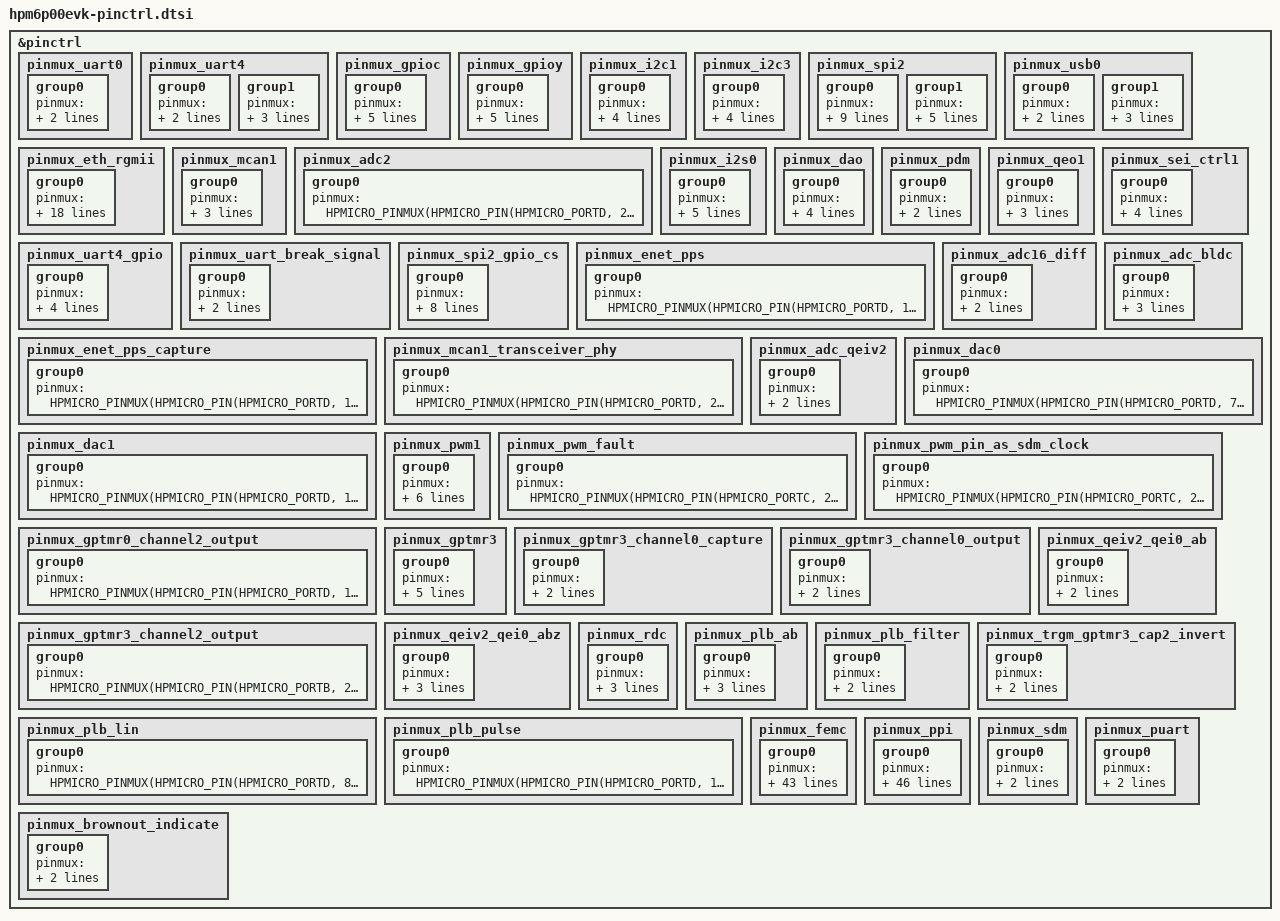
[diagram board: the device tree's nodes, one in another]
/*
* Copyright (c) 2026 HPMicro
* SPDX-License-Identifier: Apache-2.0
*/

#include "dt-bindings/pinctrl/hpmicro-pinctrl-common.h"

&pinctrl {
	pinmux_uart0: pinmux_uart0 {
		group0 {
			pinmux = <HPMICRO_PINMUX(HPMICRO_PIN(HPMICRO_PORTA, 0), IOC_TYPE_IOC, 0, 2)>,
				<HPMICRO_PINMUX(HPMICRO_PIN(HPMICRO_PORTA, 1), IOC_TYPE_IOC, 0, 2)>;
		};
	};

	pinmux_uart4: pinmux_uart4 {
		group0 {
			pinmux = <HPMICRO_PINMUX(HPMICRO_PIN(HPMICRO_PORTY, 0), IOC_TYPE_IOC, 0, 2)>,
				<HPMICRO_PINMUX(HPMICRO_PIN(HPMICRO_PORTY, 0), IOC_TYPE_PIOC, 0, 3)>;
		};

		group1 {
			pinmux = <HPMICRO_PINMUX(HPMICRO_PIN(HPMICRO_PORTY, 1), IOC_TYPE_IOC, 0, 2)>,
				<HPMICRO_PINMUX(HPMICRO_PIN(HPMICRO_PORTY, 1), IOC_TYPE_PIOC, 0, 3)>;
			bias-pull-up;
		};
	};

	pinmux_gpioc: pinmux_gpioc {
		group0 {
			pinmux = <HPMICRO_PINMUX(HPMICRO_PIN(HPMICRO_PORTC, 23), IOC_TYPE_IOC, 0, 0)>;
			drive-open-drain;
			input-enable;
			keeper-capability-disable;
			input-schmitt-enable;
		};
	};

	pinmux_gpioy: pinmux_gpioy {
		group0 {
			pinmux = <HPMICRO_PINMUX(HPMICRO_PIN(HPMICRO_PORTY, 5), IOC_TYPE_IOC, 0, 0)>,
				<HPMICRO_PINMUX(HPMICRO_PIN(HPMICRO_PORTY, 5), IOC_TYPE_PIOC, 0, 3)>;
			bias-pull-up;
			slew-rate = "fast";
			slew-pd = "100M";
		};
	};

	pinmux_i2c1: pinmux_i2c1 {
		group0 {
			pinmux = <HPMICRO_PINMUX(HPMICRO_PIN(HPMICRO_PORTC, 29), IOC_TYPE_IOC, 0, 4)>,
				<HPMICRO_PINMUX(HPMICRO_PIN(HPMICRO_PORTC, 28), IOC_TYPE_IOC, 0, 4)>;
			drive-open-drain;
			input-enable;
		};
	};

	pinmux_i2c3: pinmux_i2c3 {
		group0 {
			pinmux = <HPMICRO_PINMUX(HPMICRO_PIN(HPMICRO_PORTB, 7), IOC_TYPE_IOC, 0, 4)>,
				<HPMICRO_PINMUX(HPMICRO_PIN(HPMICRO_PORTB, 6), IOC_TYPE_IOC, 0, 4)>;
			drive-open-drain;
			input-enable;
		};
	};

	pinmux_spi2: pinmux_spi2 {
		group0 {
			pinmux = <HPMICRO_PINMUX(HPMICRO_PIN(HPMICRO_PORTY, 4), IOC_TYPE_IOC, 0, 5)>,
				<HPMICRO_PINMUX(HPMICRO_PIN(HPMICRO_PORTY, 4), IOC_TYPE_PIOC, 0, 3)>,
				<HPMICRO_PINMUX(HPMICRO_PIN(HPMICRO_PORTY, 6), IOC_TYPE_IOC, 0, 5)>,
				<HPMICRO_PINMUX(HPMICRO_PIN(HPMICRO_PORTY, 6), IOC_TYPE_PIOC, 0, 3)>,
				<HPMICRO_PINMUX(HPMICRO_PIN(HPMICRO_PORTY, 7), IOC_TYPE_IOC, 0, 5)>,
				<HPMICRO_PINMUX(HPMICRO_PIN(HPMICRO_PORTY, 7), IOC_TYPE_PIOC, 0, 3)>;
			input-enable;
			slew-rate = "fast";
			slew-pd = "100M";
		};

		group1 {
			pinmux = <HPMICRO_PINMUX(HPMICRO_PIN(HPMICRO_PORTY, 5), IOC_TYPE_IOC, 0, 0)>,
				<HPMICRO_PINMUX(HPMICRO_PIN(HPMICRO_PORTY, 5), IOC_TYPE_PIOC, 0, 3)>;
			bias-pull-up;
			slew-rate = "fast";
			slew-pd = "100M";
		};
	};

	pinmux_usb0: pinmux_usb0 {
		group0 {
			pinmux = <HPMICRO_PINMUX(HPMICRO_PIN(HPMICRO_PORTD, 0), IOC_TYPE_IOC, 1, 0)>,
				<HPMICRO_PINMUX(HPMICRO_PIN(HPMICRO_PORTD, 1), IOC_TYPE_IOC, 1, 0)>;
		};

		group1 {
			pinmux = <HPMICRO_PINMUX(HPMICRO_PIN(HPMICRO_PORTC, 25), IOC_TYPE_IOC, 0, 24)>,
				<HPMICRO_PINMUX(HPMICRO_PIN(HPMICRO_PORTC, 26), IOC_TYPE_IOC, 0, 24)>,
				<HPMICRO_PINMUX(HPMICRO_PIN(HPMICRO_PORTC, 27), IOC_TYPE_IOC, 0, 24)>;
		};
	};

	pinmux_eth_rgmii: pinmux_eth_rgmii {
		group0 {
			pinmux = <HPMICRO_PINMUX(HPMICRO_PIN(HPMICRO_PORTD, 0), IOC_TYPE_IOC, 0, 18)>,
				<HPMICRO_PINMUX(HPMICRO_PIN(HPMICRO_PORTD, 1), IOC_TYPE_IOC, 0, 18)>,
				<HPMICRO_PINMUX(HPMICRO_PIN(HPMICRO_PORTD, 3), IOC_TYPE_IOC, 0, 18)>,
				<HPMICRO_PINMUX(HPMICRO_PIN(HPMICRO_PORTD, 4), IOC_TYPE_IOC, 0, 18)>,
				<HPMICRO_PINMUX(HPMICRO_PIN(HPMICRO_PORTD, 5), IOC_TYPE_IOC, 0, 18)>,
				<HPMICRO_PINMUX(HPMICRO_PIN(HPMICRO_PORTD, 6), IOC_TYPE_IOC, 0, 18)>,
				<HPMICRO_PINMUX(HPMICRO_PIN(HPMICRO_PORTA, 18), IOC_TYPE_IOC, 0, 18)>,
				<HPMICRO_PINMUX(HPMICRO_PIN(HPMICRO_PORTA, 19), IOC_TYPE_IOC, 0, 18)>,
				<HPMICRO_PINMUX(HPMICRO_PIN(HPMICRO_PORTD, 16), IOC_TYPE_IOC, 0, 18)>,
				<HPMICRO_PINMUX(HPMICRO_PIN(HPMICRO_PORTD, 17), IOC_TYPE_IOC, 0, 18)>,
				<HPMICRO_PINMUX(HPMICRO_PIN(HPMICRO_PORTD, 18), IOC_TYPE_IOC, 0, 18)>,
				<HPMICRO_PINMUX(HPMICRO_PIN(HPMICRO_PORTD, 19), IOC_TYPE_IOC, 0, 18)>,
				<HPMICRO_PINMUX(HPMICRO_PIN(HPMICRO_PORTD, 20), IOC_TYPE_IOC, 0, 18)>,
				<HPMICRO_PINMUX(HPMICRO_PIN(HPMICRO_PORTD, 21), IOC_TYPE_IOC, 0, 18)>;
			input-schmitt-enable;
			slew-rate = "fast";
			slew-pd = "100M";
			drive-strength = "r011";
		};
	};

	pinmux_mcan1: pinmux_mcan1 {
		group0 {
			pinmux = <HPMICRO_PINMUX(HPMICRO_PIN(HPMICRO_PORTD, 30), IOC_TYPE_IOC, 0, 7)>,
				<HPMICRO_PINMUX(HPMICRO_PIN(HPMICRO_PORTD, 31), IOC_TYPE_IOC, 0, 7)>,
				<HPMICRO_PINMUX(HPMICRO_PIN(HPMICRO_PORTD, 29), IOC_TYPE_IOC, 0, 7)>;
		};
	};

	pinmux_adc2: pinmux_adc2 {
		group0 {
			pinmux = <HPMICRO_PINMUX(HPMICRO_PIN(HPMICRO_PORTD, 26), IOC_TYPE_IOC, 1, 0)>;
		};
	};

	pinmux_i2s0: pinmux_i2s0 {
		group0 {
			pinmux = <HPMICRO_PINMUX(HPMICRO_PIN(HPMICRO_PORTA, 20), IOC_TYPE_IOC, 0, 8)>,
				<HPMICRO_PINMUX(HPMICRO_PIN(HPMICRO_PORTA, 21), IOC_TYPE_IOC, 0, 8)>,
				<HPMICRO_PINMUX(HPMICRO_PIN(HPMICRO_PORTA, 22), IOC_TYPE_IOC, 0, 8)>,
				<HPMICRO_PINMUX(HPMICRO_PIN(HPMICRO_PORTB, 0), IOC_TYPE_IOC, 0, 8)>,
				<HPMICRO_PINMUX(HPMICRO_PIN(HPMICRO_PORTA, 23), IOC_TYPE_IOC, 0, 8)>;
		};
	};

	pinmux_dao: pinmux_dao {
		group0 {
			pinmux = <HPMICRO_PINMUX(HPMICRO_PIN(HPMICRO_PORTY, 3), IOC_TYPE_IOC, 0, 9)>,
				<HPMICRO_PINMUX(HPMICRO_PIN(HPMICRO_PORTY, 3), IOC_TYPE_PIOC, 0, 3)>,
				<HPMICRO_PINMUX(HPMICRO_PIN(HPMICRO_PORTY, 2), IOC_TYPE_IOC, 0, 9)>,
				<HPMICRO_PINMUX(HPMICRO_PIN(HPMICRO_PORTY, 2), IOC_TYPE_PIOC, 0, 3)>;
		};
	};

	pinmux_pdm: pinmux_pdm {
		group0 {
			pinmux = <HPMICRO_PINMUX(HPMICRO_PIN(HPMICRO_PORTD, 22), IOC_TYPE_IOC, 0, 9)>,
				<HPMICRO_PINMUX(HPMICRO_PIN(HPMICRO_PORTD, 23), IOC_TYPE_IOC, 0, 9)>;
		};
	};

	pinmux_qeo1: pinmux_qeo1 {
		group0 {
			pinmux = <HPMICRO_PINMUX(HPMICRO_PIN(HPMICRO_PORTC, 0), IOC_TYPE_IOC, 0, 21)>,
				<HPMICRO_PINMUX(HPMICRO_PIN(HPMICRO_PORTC, 1), IOC_TYPE_IOC, 0, 21)>,
				<HPMICRO_PINMUX(HPMICRO_PIN(HPMICRO_PORTC, 2), IOC_TYPE_IOC, 0, 21)>;
		};
	};

	pinmux_sei_ctrl1: pinmux_sei_ctrl1 {
		group0 {
			pinmux = <HPMICRO_PINMUX(HPMICRO_PIN(HPMICRO_PORTB, 8), IOC_TYPE_IOC, 0, 22)>,
				<HPMICRO_PINMUX(HPMICRO_PIN(HPMICRO_PORTB, 9), IOC_TYPE_IOC, 0, 22)>,
				<HPMICRO_PINMUX(HPMICRO_PIN(HPMICRO_PORTB, 10), IOC_TYPE_IOC, 0, 22)>,
				<HPMICRO_PINMUX(HPMICRO_PIN(HPMICRO_PORTB, 11), IOC_TYPE_IOC, 0, 22)>;
		};
	};

	pinmux_uart4_gpio: pinmux_uart4_gpio {
		group0 {
			pinmux = <HPMICRO_PINMUX(HPMICRO_PIN(HPMICRO_PORTY, 0), IOC_TYPE_IOC, 0, 0)>,
				<HPMICRO_PINMUX(HPMICRO_PIN(HPMICRO_PORTY, 0), IOC_TYPE_PIOC, 0, 3)>,
				<HPMICRO_PINMUX(HPMICRO_PIN(HPMICRO_PORTY, 1), IOC_TYPE_IOC, 0, 0)>,
				<HPMICRO_PINMUX(HPMICRO_PIN(HPMICRO_PORTY, 1), IOC_TYPE_PIOC, 0, 3)>;
		};
	};

	pinmux_uart_break_signal: pinmux_uart_break_signal {
		group0 {
			pinmux = <HPMICRO_PINMUX(HPMICRO_PIN(HPMICRO_PORTY, 5), IOC_TYPE_IOC, 0, 0)>,
				<HPMICRO_PINMUX(HPMICRO_PIN(HPMICRO_PORTY, 5), IOC_TYPE_PIOC, 0, 3)>;
		};
	};

	pinmux_spi2_gpio_cs: pinmux_spi2_gpio_cs {
		group0 {
			pinmux = <HPMICRO_PINMUX(HPMICRO_PIN(HPMICRO_PORTY, 5), IOC_TYPE_IOC, 0, 0)>,
				<HPMICRO_PINMUX(HPMICRO_PIN(HPMICRO_PORTY, 5), IOC_TYPE_PIOC, 0, 3)>,
				<HPMICRO_PINMUX(HPMICRO_PIN(HPMICRO_PORTY, 4), IOC_TYPE_IOC, 0, 5)>,
				<HPMICRO_PINMUX(HPMICRO_PIN(HPMICRO_PORTY, 4), IOC_TYPE_PIOC, 0, 3)>,
				<HPMICRO_PINMUX(HPMICRO_PIN(HPMICRO_PORTY, 6), IOC_TYPE_IOC, 0, 5)>,
				<HPMICRO_PINMUX(HPMICRO_PIN(HPMICRO_PORTY, 6), IOC_TYPE_PIOC, 0, 3)>,
				<HPMICRO_PINMUX(HPMICRO_PIN(HPMICRO_PORTY, 7), IOC_TYPE_IOC, 0, 5)>,
				<HPMICRO_PINMUX(HPMICRO_PIN(HPMICRO_PORTY, 7), IOC_TYPE_PIOC, 0, 3)>;
		};
	};

	pinmux_enet_pps: pinmux_enet_pps {
		group0 {
			pinmux = <HPMICRO_PINMUX(HPMICRO_PIN(HPMICRO_PORTD, 11), IOC_TYPE_IOC, 0, 25)>;
		};
	};

	pinmux_enet_pps_capture: pinmux_enet_pps_capture {
		group0 {
			pinmux = <HPMICRO_PINMUX(HPMICRO_PIN(HPMICRO_PORTD, 12), IOC_TYPE_IOC, 0, 25)>;
		};
	};

	pinmux_mcan1_transceiver_phy: pinmux_mcan1_transceiver_phy {
		group0 {
			pinmux = <HPMICRO_PINMUX(HPMICRO_PIN(HPMICRO_PORTD, 29), IOC_TYPE_IOC, 0, 0)>;
		};
	};

	pinmux_adc16_diff: pinmux_adc16_diff {
		group0 {
			pinmux = <HPMICRO_PINMUX(HPMICRO_PIN(HPMICRO_PORTD, 24), IOC_TYPE_IOC, 1, 0)>,
				<HPMICRO_PINMUX(HPMICRO_PIN(HPMICRO_PORTD, 25), IOC_TYPE_IOC, 1, 0)>;
		};
	};

	pinmux_adc_bldc: pinmux_adc_bldc {
		group0 {
			pinmux = <HPMICRO_PINMUX(HPMICRO_PIN(HPMICRO_PORTD, 14), IOC_TYPE_IOC, 1, 0)>,
				<HPMICRO_PINMUX(HPMICRO_PIN(HPMICRO_PORTD, 24), IOC_TYPE_IOC, 1, 0)>,
				<HPMICRO_PINMUX(HPMICRO_PIN(HPMICRO_PORTD, 25), IOC_TYPE_IOC, 1, 0)>;
		};
	};

	pinmux_adc_qeiv2: pinmux_adc_qeiv2 {
		group0 {
			pinmux = <HPMICRO_PINMUX(HPMICRO_PIN(HPMICRO_PORTD, 25), IOC_TYPE_IOC, 1, 0)>,
				<HPMICRO_PINMUX(HPMICRO_PIN(HPMICRO_PORTD, 14), IOC_TYPE_IOC, 1, 0)>;
		};
	};

	pinmux_dac0: pinmux_dac0 {
		group0 {
			pinmux = <HPMICRO_PINMUX(HPMICRO_PIN(HPMICRO_PORTD, 7), IOC_TYPE_IOC, 1, 0)>;
		};
	};

	pinmux_dac1: pinmux_dac1 {
		group0 {
			pinmux = <HPMICRO_PINMUX(HPMICRO_PIN(HPMICRO_PORTD, 17), IOC_TYPE_IOC, 1, 0)>;
		};
	};

	pinmux_pwm1: pinmux_pwm1 {
		group0 {
			pinmux = <HPMICRO_PINMUX(HPMICRO_PIN(HPMICRO_PORTD, 8), IOC_TYPE_IOC, 0, 16)>,
				<HPMICRO_PINMUX(HPMICRO_PIN(HPMICRO_PORTD, 9), IOC_TYPE_IOC, 0, 16)>,
				<HPMICRO_PINMUX(HPMICRO_PIN(HPMICRO_PORTD, 10), IOC_TYPE_IOC, 0, 16)>,
				<HPMICRO_PINMUX(HPMICRO_PIN(HPMICRO_PORTD, 11), IOC_TYPE_IOC, 0, 16)>,
				<HPMICRO_PINMUX(HPMICRO_PIN(HPMICRO_PORTD, 12), IOC_TYPE_IOC, 0, 16)>,
				<HPMICRO_PINMUX(HPMICRO_PIN(HPMICRO_PORTD, 13), IOC_TYPE_IOC, 0, 16)>;
		};
	};

	pinmux_pwm_fault: pinmux_pwm_fault {
		group0 {
			pinmux = <HPMICRO_PINMUX(HPMICRO_PIN(HPMICRO_PORTC, 2), IOC_TYPE_IOC, 0, 17)>;
		};
	};

	pinmux_pwm_pin_as_sdm_clock: pinmux_pwm_pin_as_sdm_clock {
		group0 {
			pinmux = <HPMICRO_PINMUX(HPMICRO_PIN(HPMICRO_PORTC, 2), IOC_TYPE_IOC, 0, 16)>;
		};
	};

	pinmux_gptmr0_channel2_output: pinmux_gptmr0_channel2_output {
		group0 {
			pinmux = <HPMICRO_PINMUX(HPMICRO_PIN(HPMICRO_PORTD, 10), IOC_TYPE_IOC, 0, 1)>;
		};
	};

	pinmux_gptmr3: pinmux_gptmr3 {
		group0 {
			pinmux = <HPMICRO_PINMUX(HPMICRO_PIN(HPMICRO_PORTY, 0), IOC_TYPE_IOC, 0, 1)>,
				<HPMICRO_PINMUX(HPMICRO_PIN(HPMICRO_PORTY, 0), IOC_TYPE_PIOC, 0, 3)>,
				<HPMICRO_PINMUX(HPMICRO_PIN(HPMICRO_PORTY, 1), IOC_TYPE_IOC, 0, 1)>,
				<HPMICRO_PINMUX(HPMICRO_PIN(HPMICRO_PORTY, 1), IOC_TYPE_PIOC, 0, 3)>,
				<HPMICRO_PINMUX(HPMICRO_PIN(HPMICRO_PORTB, 21), IOC_TYPE_IOC, 0, 1)>;
		};
	};

	pinmux_gptmr3_channel0_capture: pinmux_gptmr3_channel0_capture {
		group0 {
			pinmux = <HPMICRO_PINMUX(HPMICRO_PIN(HPMICRO_PORTY, 1), IOC_TYPE_IOC, 0, 1)>,
				<HPMICRO_PINMUX(HPMICRO_PIN(HPMICRO_PORTY, 1), IOC_TYPE_PIOC, 0, 3)>;
		};
	};

	pinmux_gptmr3_channel0_output: pinmux_gptmr3_channel0_output {
		group0 {
			pinmux = <HPMICRO_PINMUX(HPMICRO_PIN(HPMICRO_PORTY, 0), IOC_TYPE_IOC, 0, 1)>,
				<HPMICRO_PINMUX(HPMICRO_PIN(HPMICRO_PORTY, 0), IOC_TYPE_PIOC, 0, 3)>;
		};
	};

	pinmux_gptmr3_channel2_output: pinmux_gptmr3_channel2_output {
		group0 {
			pinmux = <HPMICRO_PINMUX(HPMICRO_PIN(HPMICRO_PORTB, 21), IOC_TYPE_IOC, 0, 1)>;
		};
	};

	pinmux_qeiv2_qei0_ab: pinmux_qeiv2_qei0_ab {
		group0 {
			pinmux = <HPMICRO_PINMUX(HPMICRO_PIN(HPMICRO_PORTB, 23), IOC_TYPE_IOC, 0, 20)>,
				<HPMICRO_PINMUX(HPMICRO_PIN(HPMICRO_PORTB, 22), IOC_TYPE_IOC, 0, 20)>;
		};
	};

	pinmux_qeiv2_qei0_abz: pinmux_qeiv2_qei0_abz {
		group0 {
			pinmux = <HPMICRO_PINMUX(HPMICRO_PIN(HPMICRO_PORTB, 23), IOC_TYPE_IOC, 0, 20)>,
				<HPMICRO_PINMUX(HPMICRO_PIN(HPMICRO_PORTB, 22), IOC_TYPE_IOC, 0, 20)>,
				<HPMICRO_PINMUX(HPMICRO_PIN(HPMICRO_PORTB, 21), IOC_TYPE_IOC, 0, 20)>;
		};
	};

	pinmux_rdc: pinmux_rdc {
		group0 {
			pinmux = <HPMICRO_PINMUX(HPMICRO_PIN(HPMICRO_PORTA, 17), IOC_TYPE_IOC, 0, 20)>,
				<HPMICRO_PINMUX(HPMICRO_PIN(HPMICRO_PORTD, 14), IOC_TYPE_IOC, 1, 0)>,
				<HPMICRO_PINMUX(HPMICRO_PIN(HPMICRO_PORTD, 24), IOC_TYPE_IOC, 1, 0)>;
		};
	};

	pinmux_plb_ab: pinmux_plb_ab {
		group0 {
			pinmux = <HPMICRO_PINMUX(HPMICRO_PIN(HPMICRO_PORTB, 23), IOC_TYPE_IOC, 0, 17)>,
				<HPMICRO_PINMUX(HPMICRO_PIN(HPMICRO_PORTB, 22), IOC_TYPE_IOC, 0, 17)>,
				<HPMICRO_PINMUX(HPMICRO_PIN(HPMICRO_PORTB, 21), IOC_TYPE_IOC, 0, 17)>;
		};
	};

	pinmux_plb_filter: pinmux_plb_filter {
		group0 {
			pinmux = <HPMICRO_PINMUX(HPMICRO_PIN(HPMICRO_PORTD, 10), IOC_TYPE_IOC, 0, 17)>,
				<HPMICRO_PINMUX(HPMICRO_PIN(HPMICRO_PORTD, 12), IOC_TYPE_IOC, 0, 17)>;
		};
	};

	pinmux_plb_lin: pinmux_plb_lin {
		group0 {
			pinmux = <HPMICRO_PINMUX(HPMICRO_PIN(HPMICRO_PORTD, 8), IOC_TYPE_IOC, 0, 17)>;
		};
	};

	pinmux_plb_pulse: pinmux_plb_pulse {
		group0 {
			pinmux = <HPMICRO_PINMUX(HPMICRO_PIN(HPMICRO_PORTD, 10), IOC_TYPE_IOC, 0, 17)>;
		};
	};

	pinmux_trgm_gptmr3_cap2_invert: pinmux_trgm_gptmr3_cap2_invert {
		group0 {
			pinmux = <HPMICRO_PINMUX(HPMICRO_PIN(HPMICRO_PORTY, 1), IOC_TYPE_IOC, 0, 17)>,
				<HPMICRO_PINMUX(HPMICRO_PIN(HPMICRO_PORTY, 1), IOC_TYPE_PIOC, 0, 3)>;
		};
	};

	pinmux_femc: pinmux_femc {
		group0 {
			pinmux = <HPMICRO_PINMUX(HPMICRO_PIN(HPMICRO_PORTB, 0), IOC_TYPE_IOC, 0, 12)>,
				<HPMICRO_PINMUX(HPMICRO_PIN(HPMICRO_PORTB, 1), IOC_TYPE_IOC, 0, 12)>,
				<HPMICRO_PINMUX(HPMICRO_PIN(HPMICRO_PORTB, 2), IOC_TYPE_IOC, 0, 12)>,
				<HPMICRO_PINMUX(HPMICRO_PIN(HPMICRO_PORTB, 3), IOC_TYPE_IOC, 0, 12)>,
				<HPMICRO_PINMUX(HPMICRO_PIN(HPMICRO_PORTB, 4), IOC_TYPE_IOC, 0, 12)>,
				<HPMICRO_PINMUX(HPMICRO_PIN(HPMICRO_PORTB, 5), IOC_TYPE_IOC, 0, 12)>,
				<HPMICRO_PINMUX(HPMICRO_PIN(HPMICRO_PORTB, 12), IOC_TYPE_IOC, 0, 12)>,
				<HPMICRO_PINMUX(HPMICRO_PIN(HPMICRO_PORTB, 13), IOC_TYPE_IOC, 0, 12)>,
				<HPMICRO_PINMUX(HPMICRO_PIN(HPMICRO_PORTB, 14), IOC_TYPE_IOC, 0, 12)>,
				<HPMICRO_PINMUX(HPMICRO_PIN(HPMICRO_PORTB, 15), IOC_TYPE_IOC, 0, 12)>,
				<HPMICRO_PINMUX(HPMICRO_PIN(HPMICRO_PORTA, 15), IOC_TYPE_IOC, 0, 12)>,
				<HPMICRO_PINMUX(HPMICRO_PIN(HPMICRO_PORTB, 16), IOC_TYPE_IOC, 0, 12)>,
				<HPMICRO_PINMUX(HPMICRO_PIN(HPMICRO_PORTB, 17), IOC_TYPE_IOC, 0, 12)>,
				<HPMICRO_PINMUX(HPMICRO_PIN(HPMICRO_PORTC, 12), IOC_TYPE_IOC, 0, 12)>,
				<HPMICRO_PINMUX(HPMICRO_PIN(HPMICRO_PORTC, 13), IOC_TYPE_IOC, 0, 12)>,
				<HPMICRO_PINMUX(HPMICRO_PIN(HPMICRO_PORTC, 14), IOC_TYPE_IOC, 0, 12)>,
				<HPMICRO_PINMUX(HPMICRO_PIN(HPMICRO_PORTC, 15), IOC_TYPE_IOC, 0, 12)>,
				<HPMICRO_PINMUX(HPMICRO_PIN(HPMICRO_PORTC, 16), IOC_TYPE_IOC, 0, 12)>,
				<HPMICRO_PINMUX(HPMICRO_PIN(HPMICRO_PORTC, 17), IOC_TYPE_IOC, 0, 12)>,
				<HPMICRO_PINMUX(HPMICRO_PIN(HPMICRO_PORTC, 18), IOC_TYPE_IOC, 0, 12)>,
				<HPMICRO_PINMUX(HPMICRO_PIN(HPMICRO_PORTC, 19), IOC_TYPE_IOC, 0, 12)>,
				<HPMICRO_PINMUX(HPMICRO_PIN(HPMICRO_PORTC, 4), IOC_TYPE_IOC, 0, 12)>,
				<HPMICRO_PINMUX(HPMICRO_PIN(HPMICRO_PORTC, 5), IOC_TYPE_IOC, 0, 12)>,
				<HPMICRO_PINMUX(HPMICRO_PIN(HPMICRO_PORTC, 6), IOC_TYPE_IOC, 0, 12)>,
				<HPMICRO_PINMUX(HPMICRO_PIN(HPMICRO_PORTC, 7), IOC_TYPE_IOC, 0, 12)>,
				<HPMICRO_PINMUX(HPMICRO_PIN(HPMICRO_PORTC, 8), IOC_TYPE_IOC, 0, 12)>,
				<HPMICRO_PINMUX(HPMICRO_PIN(HPMICRO_PORTC, 9), IOC_TYPE_IOC, 0, 12)>,
				<HPMICRO_PINMUX(HPMICRO_PIN(HPMICRO_PORTC, 10), IOC_TYPE_IOC, 0, 12)>,
				<HPMICRO_PINMUX(HPMICRO_PIN(HPMICRO_PORTC, 11), IOC_TYPE_IOC, 0, 12)>,
				<HPMICRO_PINMUX(HPMICRO_PIN(HPMICRO_PORTC, 20), IOC_TYPE_IOC, 0, 12)>,
				<HPMICRO_PINMUX(HPMICRO_PIN(HPMICRO_PORTC, 3), IOC_TYPE_IOC, 0, 12)>,
				<HPMICRO_PINMUX(HPMICRO_PIN(HPMICRO_PORTA, 13), IOC_TYPE_IOC, 0, 12)>,
				<HPMICRO_PINMUX(HPMICRO_PIN(HPMICRO_PORTA, 14), IOC_TYPE_IOC, 0, 12)>,
				<HPMICRO_PINMUX(HPMICRO_PIN(HPMICRO_PORTA, 12), IOC_TYPE_IOC, 0, 12)>,
				<HPMICRO_PINMUX(HPMICRO_PIN(HPMICRO_PORTA, 10), IOC_TYPE_IOC, 0, 12)>,
				<HPMICRO_PINMUX(HPMICRO_PIN(HPMICRO_PORTA, 11), IOC_TYPE_IOC, 0, 12)>,
				<HPMICRO_PINMUX(HPMICRO_PIN(HPMICRO_PORTB, 18), IOC_TYPE_IOC, 0, 12)>,
				<HPMICRO_PINMUX(HPMICRO_PIN(HPMICRO_PORTB, 19), IOC_TYPE_IOC, 0, 12)>,
				<HPMICRO_PINMUX(HPMICRO_PIN(HPMICRO_PORTA, 9), IOC_TYPE_IOC, 0, 12)>,
				<HPMICRO_PINMUX(HPMICRO_PIN(HPMICRO_PORTB, 21), IOC_TYPE_IOC, 0, 12)>,
				<HPMICRO_PINMUX(HPMICRO_PIN(HPMICRO_PORTB, 22), IOC_TYPE_IOC, 0, 12)>,
				<HPMICRO_PINMUX(HPMICRO_PIN(HPMICRO_PORTC, 21), IOC_TYPE_IOC, 0, 12)>,
				<HPMICRO_PINMUX(HPMICRO_PIN(HPMICRO_PORTB, 28), IOC_TYPE_IOC, 0, 12)>;
		};
	};

	pinmux_ppi: pinmux_ppi {
		group0 {
			pinmux = <HPMICRO_PINMUX(HPMICRO_PIN(HPMICRO_PORTC, 12), IOC_TYPE_IOC, 0, 13)>,
				<HPMICRO_PINMUX(HPMICRO_PIN(HPMICRO_PORTC, 13), IOC_TYPE_IOC, 0, 13)>,
				<HPMICRO_PINMUX(HPMICRO_PIN(HPMICRO_PORTC, 14), IOC_TYPE_IOC, 0, 13)>,
				<HPMICRO_PINMUX(HPMICRO_PIN(HPMICRO_PORTC, 15), IOC_TYPE_IOC, 0, 13)>,
				<HPMICRO_PINMUX(HPMICRO_PIN(HPMICRO_PORTC, 16), IOC_TYPE_IOC, 0, 13)>,
				<HPMICRO_PINMUX(HPMICRO_PIN(HPMICRO_PORTC, 17), IOC_TYPE_IOC, 0, 13)>,
				<HPMICRO_PINMUX(HPMICRO_PIN(HPMICRO_PORTC, 18), IOC_TYPE_IOC, 0, 13)>,
				<HPMICRO_PINMUX(HPMICRO_PIN(HPMICRO_PORTC, 19), IOC_TYPE_IOC, 0, 13)>,
				<HPMICRO_PINMUX(HPMICRO_PIN(HPMICRO_PORTC, 4), IOC_TYPE_IOC, 0, 13)>,
				<HPMICRO_PINMUX(HPMICRO_PIN(HPMICRO_PORTC, 5), IOC_TYPE_IOC, 0, 13)>,
				<HPMICRO_PINMUX(HPMICRO_PIN(HPMICRO_PORTC, 6), IOC_TYPE_IOC, 0, 13)>,
				<HPMICRO_PINMUX(HPMICRO_PIN(HPMICRO_PORTC, 7), IOC_TYPE_IOC, 0, 13)>,
				<HPMICRO_PINMUX(HPMICRO_PIN(HPMICRO_PORTC, 8), IOC_TYPE_IOC, 0, 13)>,
				<HPMICRO_PINMUX(HPMICRO_PIN(HPMICRO_PORTC, 9), IOC_TYPE_IOC, 0, 13)>,
				<HPMICRO_PINMUX(HPMICRO_PIN(HPMICRO_PORTC, 10), IOC_TYPE_IOC, 0, 13)>,
				<HPMICRO_PINMUX(HPMICRO_PIN(HPMICRO_PORTC, 11), IOC_TYPE_IOC, 0, 13)>,
				<HPMICRO_PINMUX(HPMICRO_PIN(HPMICRO_PORTB, 0), IOC_TYPE_IOC, 0, 13)>,
				<HPMICRO_PINMUX(HPMICRO_PIN(HPMICRO_PORTB, 1), IOC_TYPE_IOC, 0, 13)>,
				<HPMICRO_PINMUX(HPMICRO_PIN(HPMICRO_PORTB, 2), IOC_TYPE_IOC, 0, 13)>,
				<HPMICRO_PINMUX(HPMICRO_PIN(HPMICRO_PORTB, 3), IOC_TYPE_IOC, 0, 13)>,
				<HPMICRO_PINMUX(HPMICRO_PIN(HPMICRO_PORTB, 4), IOC_TYPE_IOC, 0, 13)>,
				<HPMICRO_PINMUX(HPMICRO_PIN(HPMICRO_PORTB, 5), IOC_TYPE_IOC, 0, 13)>,
				<HPMICRO_PINMUX(HPMICRO_PIN(HPMICRO_PORTB, 12), IOC_TYPE_IOC, 0, 13)>,
				<HPMICRO_PINMUX(HPMICRO_PIN(HPMICRO_PORTB, 13), IOC_TYPE_IOC, 0, 13)>,
				<HPMICRO_PINMUX(HPMICRO_PIN(HPMICRO_PORTB, 14), IOC_TYPE_IOC, 0, 13)>,
				<HPMICRO_PINMUX(HPMICRO_PIN(HPMICRO_PORTB, 15), IOC_TYPE_IOC, 0, 13)>,
				<HPMICRO_PINMUX(HPMICRO_PIN(HPMICRO_PORTA, 15), IOC_TYPE_IOC, 0, 13)>,
				<HPMICRO_PINMUX(HPMICRO_PIN(HPMICRO_PORTB, 16), IOC_TYPE_IOC, 0, 13)>,
				<HPMICRO_PINMUX(HPMICRO_PIN(HPMICRO_PORTB, 17), IOC_TYPE_IOC, 0, 13)>,
				<HPMICRO_PINMUX(HPMICRO_PIN(HPMICRO_PORTB, 18), IOC_TYPE_IOC, 0, 13)>,
				<HPMICRO_PINMUX(HPMICRO_PIN(HPMICRO_PORTC, 20), IOC_TYPE_IOC, 0, 13)>,
				<HPMICRO_PINMUX(HPMICRO_PIN(HPMICRO_PORTC, 3), IOC_TYPE_IOC, 0, 13)>,
				<HPMICRO_PINMUX(HPMICRO_PIN(HPMICRO_PORTA, 10), IOC_TYPE_IOC, 0, 13)>,
				<HPMICRO_PINMUX(HPMICRO_PIN(HPMICRO_PORTA, 11), IOC_TYPE_IOC, 0, 13)>,
				<HPMICRO_PINMUX(HPMICRO_PIN(HPMICRO_PORTA, 12), IOC_TYPE_IOC, 0, 13)>,
				<HPMICRO_PINMUX(HPMICRO_PIN(HPMICRO_PORTA, 14), IOC_TYPE_IOC, 0, 13)>,
				<HPMICRO_PINMUX(HPMICRO_PIN(HPMICRO_PORTB, 22), IOC_TYPE_IOC, 0, 13)>,
				<HPMICRO_PINMUX(HPMICRO_PIN(HPMICRO_PORTC, 21), IOC_TYPE_IOC, 0, 13)>,
				<HPMICRO_PINMUX(HPMICRO_PIN(HPMICRO_PORTB, 20), IOC_TYPE_IOC, 0, 13)>,
				<HPMICRO_PINMUX(HPMICRO_PIN(HPMICRO_PORTA, 9), IOC_TYPE_IOC, 0, 13)>,
				<HPMICRO_PINMUX(HPMICRO_PIN(HPMICRO_PORTA, 13), IOC_TYPE_IOC, 0, 13)>,
				<HPMICRO_PINMUX(HPMICRO_PIN(HPMICRO_PORTB, 21), IOC_TYPE_IOC, 0, 13)>,
				<HPMICRO_PINMUX(HPMICRO_PIN(HPMICRO_PORTB, 27), IOC_TYPE_IOC, 0, 13)>,
				<HPMICRO_PINMUX(HPMICRO_PIN(HPMICRO_PORTB, 26), IOC_TYPE_IOC, 0, 13)>,
				<HPMICRO_PINMUX(HPMICRO_PIN(HPMICRO_PORTB, 25), IOC_TYPE_IOC, 0, 13)>,
				<HPMICRO_PINMUX(HPMICRO_PIN(HPMICRO_PORTB, 19), IOC_TYPE_IOC, 0, 13)>;
		};
	};

	pinmux_sdm: pinmux_sdm {
		group0 {
			pinmux = <HPMICRO_PINMUX(HPMICRO_PIN(HPMICRO_PORTC, 0), IOC_TYPE_IOC, 0, 23)>,
				<HPMICRO_PINMUX(HPMICRO_PIN(HPMICRO_PORTC, 1), IOC_TYPE_IOC, 0, 23)>;
		};
	};

	pinmux_brownout_indicate: pinmux_brownout_indicate {
		group0 {
			pinmux = <HPMICRO_PINMUX(HPMICRO_PIN(HPMICRO_PORTY, 7), IOC_TYPE_IOC, 0, 0)>,
				<HPMICRO_PINMUX(HPMICRO_PIN(HPMICRO_PORTY, 7), IOC_TYPE_PIOC, 0, 3)>;
		};
	};

	pinmux_puart: pinmux_puart {
		group0 {
			pinmux = <HPMICRO_PINMUX(HPMICRO_PIN(HPMICRO_PORTY, 0), IOC_TYPE_PIOC, 0, 1)>,
				<HPMICRO_PINMUX(HPMICRO_PIN(HPMICRO_PORTY, 1), IOC_TYPE_PIOC, 0, 1)>;
		};
	};
};
